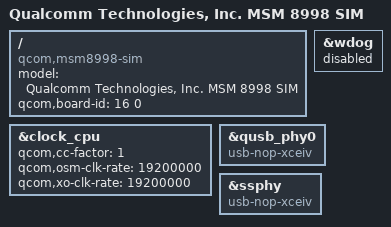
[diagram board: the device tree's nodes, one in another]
/* Copyright (c) 2015-2016, The Linux Foundation. All rights reserved.
 *
 * This program is free software; you can redistribute it and/or modify
 * it under the terms of the GNU General Public License version 2 and
 * only version 2 as published by the Free Software Foundation.
 *
 * This program is distributed in the hope that it will be useful,
 * but WITHOUT ANY WARRANTY; without even the implied warranty of
 * MERCHANTABILITY or FITNESS FOR A PARTICULAR PURPOSE.  See the
 * GNU General Public License for more details.
 */


/dts-v1/;
/memreserve/ 0x90000000 0x00000100;

#include "msm8998.dtsi"
#include "msm8998-sim.dtsi"

/ {
	model = "Qualcomm Technologies, Inc. MSM 8998 SIM";
	compatible = "qcom,msm8998-sim", "qcom,msm8998", "qcom,sim";
	qcom,board-id = <16 0>;
};

&wdog {
	status = "disabled";
};

&clock_cpu {
	qcom,cc-factor = <1>;
	qcom,osm-clk-rate = <19200000>;
	qcom,xo-clk-rate = <19200000>;
};

&qusb_phy0 {
	compatible =  "usb-nop-xceiv";
};

&ssphy {
	compatible =  "usb-nop-xceiv";
};
